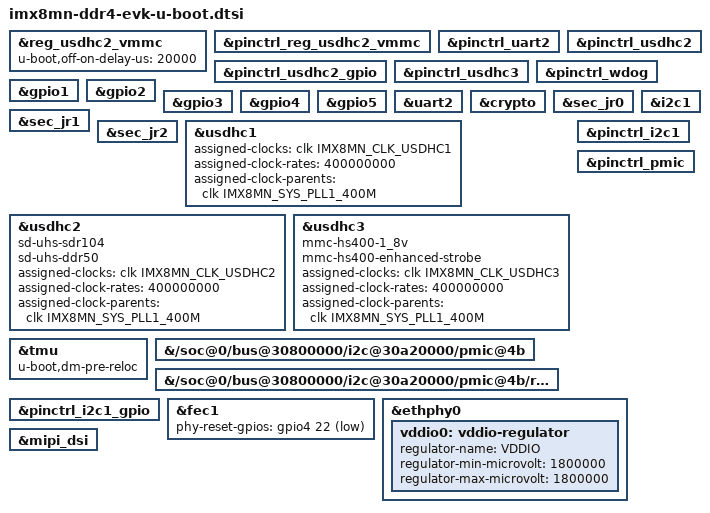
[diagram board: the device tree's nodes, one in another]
// SPDX-License-Identifier: GPL-2.0+
/*
 * Copyright 2019, 2021 NXP
 */

#include "imx8mn-u-boot.dtsi"

&reg_usdhc2_vmmc {
	u-boot,dm-spl;
	u-boot,off-on-delay-us = <20000>;
};

&pinctrl_reg_usdhc2_vmmc {
	u-boot,dm-spl;
};

&pinctrl_uart2 {
	u-boot,dm-spl;
};

&pinctrl_usdhc2_gpio {
	u-boot,dm-spl;
};

&pinctrl_usdhc2 {
	u-boot,dm-spl;
};

&pinctrl_usdhc3 {
	u-boot,dm-spl;
};

&pinctrl_wdog {
	u-boot,dm-spl;
};

&gpio1 {
	u-boot,dm-spl;
};

&gpio2 {
	u-boot,dm-spl;
};

&gpio3 {
	u-boot,dm-spl;
};

&gpio4 {
	u-boot,dm-spl;
};

&gpio5 {
	u-boot,dm-spl;
};

&uart2 {
	u-boot,dm-spl;
};

&crypto {
	u-boot,dm-spl;
};

&sec_jr0 {
	u-boot,dm-spl;
};

&sec_jr1 {
	u-boot,dm-spl;
};

&sec_jr2 {
	u-boot,dm-spl;
};

&usdhc1 {
	u-boot,dm-spl;
	assigned-clocks = <&clk IMX8MN_CLK_USDHC1>;
	assigned-clock-rates = <400000000>;
	assigned-clock-parents = <&clk IMX8MN_SYS_PLL1_400M>;
};

&usdhc2 {
	u-boot,dm-spl;
	sd-uhs-sdr104;
	sd-uhs-ddr50;
	assigned-clocks = <&clk IMX8MN_CLK_USDHC2>;
	assigned-clock-rates = <400000000>;
	assigned-clock-parents = <&clk IMX8MN_SYS_PLL1_400M>;
};

&usdhc3 {
	u-boot,dm-spl;
	mmc-hs400-1_8v;
	mmc-hs400-enhanced-strobe;
	assigned-clocks = <&clk IMX8MN_CLK_USDHC3>;
	assigned-clock-rates = <400000000>;
	assigned-clock-parents = <&clk IMX8MN_SYS_PLL1_400M>;
};

&tmu {
	u-boot,dm-pre-reloc;
};

&i2c1 {
	u-boot,dm-spl;
};

&{/soc@0/bus@30800000/i2c@30a20000/pmic@4b} {
	u-boot,dm-spl;
};

&{/soc@0/bus@30800000/i2c@30a20000/pmic@4b/regulators} {
	u-boot,dm-spl;
};

&pinctrl_i2c1 {
	u-boot,dm-spl;
};

&pinctrl_i2c1_gpio {
	u-boot,dm-spl;
};

&pinctrl_pmic {
	u-boot,dm-spl;
};

&fec1 {
	phy-reset-gpios = <&gpio4 22 GPIO_ACTIVE_LOW>;
};

&ethphy0 {
	vddio0: vddio-regulator {
		regulator-name = "VDDIO";
		regulator-min-microvolt = <1800000>;
		regulator-max-microvolt = <1800000>;
	};
};

&mipi_dsi {
	/delete-property/ assigned-clocks;
	/delete-property/ assigned-clock-parents;
	/delete-property/ assigned-clock-rates;
};
